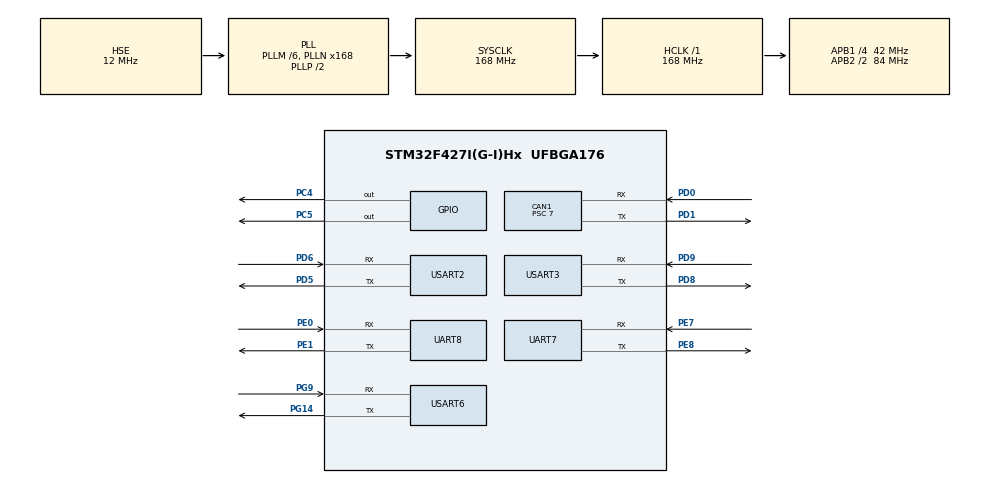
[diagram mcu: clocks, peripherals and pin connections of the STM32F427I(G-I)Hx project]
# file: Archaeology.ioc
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CAN1.ABOM=ENABLE
CAN1.AWUM=ENABLE
CAN1.BS1=CAN_BS1_2TQ
CAN1.BS2=CAN_BS2_3TQ
CAN1.CalculateBaudRate=1000000
CAN1.CalculateTimeBit=999.99
CAN1.CalculateTimeQuantum=166.66666666666669
CAN1.Mode=CAN_MODE_NORMAL
CAN1.Prescaler=7
CAN1.TXFP=ENABLE
Dma.Request0=USART3_TX
Dma.Request1=UART7_TX
Dma.Request2=UART8_TX
Dma.Request3=USART2_TX
Dma.Request4=USART6_TX
Dma.UART7_TX.1.Direction=DMA_MEMORY_TO_PERIPH
Dma.UART7_TX.1.FIFOMode=DMA_FIFOMODE_DISABLE
Dma.UART7_TX.1.Instance=DMA1_Stream1
Dma.UART7_TX.1.MemDataAlignment=DMA_MDATAALIGN_BYTE
Dma.UART7_TX.1.MemInc=DMA_MINC_ENABLE
Dma.UART7_TX.1.Mode=DMA_NORMAL
Dma.UART7_TX.1.PeriphDataAlignment=DMA_PDATAALIGN_BYTE
Dma.UART7_TX.1.PeriphInc=DMA_PINC_DISABLE
Dma.UART7_TX.1.Priority=DMA_PRIORITY_LOW
Dma.UART8_TX.2.Direction=DMA_MEMORY_TO_PERIPH
Dma.UART8_TX.2.FIFOMode=DMA_FIFOMODE_DISABLE
Dma.UART8_TX.2.Instance=DMA1_Stream0
Dma.UART8_TX.2.MemDataAlignment=DMA_MDATAALIGN_BYTE
Dma.UART8_TX.2.MemInc=DMA_MINC_ENABLE
Dma.UART8_TX.2.Mode=DMA_NORMAL
Dma.UART8_TX.2.PeriphDataAlignment=DMA_PDATAALIGN_BYTE
Dma.UART8_TX.2.PeriphInc=DMA_PINC_DISABLE
Dma.UART8_TX.2.Priority=DMA_PRIORITY_LOW
Dma.USART2_TX.3.Direction=DMA_MEMORY_TO_PERIPH
Dma.USART2_TX.3.FIFOMode=DMA_FIFOMODE_DISABLE
Dma.USART2_TX.3.Instance=DMA1_Stream6
Dma.USART2_TX.3.MemDataAlignment=DMA_MDATAALIGN_BYTE
Dma.USART2_TX.3.MemInc=DMA_MINC_ENABLE
Dma.USART2_TX.3.Mode=DMA_NORMAL
Dma.USART2_TX.3.PeriphDataAlignment=DMA_PDATAALIGN_BYTE
Dma.USART2_TX.3.PeriphInc=DMA_PINC_DISABLE
Dma.USART2_TX.3.Priority=DMA_PRIORITY_LOW
Dma.USART3_TX.0.Direction=DMA_MEMORY_TO_PERIPH
Dma.USART3_TX.0.FIFOMode=DMA_FIFOMODE_DISABLE
Dma.USART3_TX.0.Instance=DMA1_Stream3
Dma.USART3_TX.0.MemDataAlignment=DMA_MDATAALIGN_BYTE
Dma.USART3_TX.0.MemInc=DMA_MINC_ENABLE
Dma.USART3_TX.0.Mode=DMA_NORMAL
Dma.USART3_TX.0.PeriphDataAlignment=DMA_PDATAALIGN_BYTE
Dma.USART3_TX.0.PeriphInc=DMA_PINC_DISABLE
Dma.USART3_TX.0.Priority=DMA_PRIORITY_LOW
Dma.USART6_TX.4.Direction=DMA_MEMORY_TO_PERIPH
Dma.USART6_TX.4.FIFOMode=DMA_FIFOMODE_DISABLE
Dma.USART6_TX.4.Instance=DMA2_Stream6
Dma.USART6_TX.4.MemDataAlignment=DMA_MDATAALIGN_BYTE
Dma.USART6_TX.4.MemInc=DMA_MINC_ENABLE
Dma.USART6_TX.4.Mode=DMA_NORMAL
Dma.USART6_TX.4.PeriphDataAlignment=DMA_PDATAALIGN_BYTE
Dma.USART6_TX.4.PeriphInc=DMA_PINC_DISABLE
Dma.USART6_TX.4.Priority=DMA_PRIORITY_LOW
Mcu.Family=STM32F4
Mcu.Name=STM32F427I(G-I)Hx
Mcu.Package=UFBGA176
NVIC.CAN1_RX0_IRQn=true\:0\:0\:false\:false\:true\:true\:true
NVIC.CAN1_TX_IRQn=true\:0\:0\:false\:false\:true\:true\:true
NVIC.DMA1_Stream0_IRQn=true\:0\:0\:false\:false\:true\:false\:true
NVIC.DMA1_Stream1_IRQn=true\:0\:0\:false\:false\:true\:false\:true
NVIC.DMA1_Stream3_IRQn=true\:0\:0\:false\:false\:true\:false\:true
NVIC.DMA1_Stream6_IRQn=true\:0\:0\:false\:false\:true\:false\:true
NVIC.DMA2_Stream6_IRQn=true\:0\:0\:false\:false\:true\:false\:true
NVIC.PriorityGroup=NVIC_PRIORITYGROUP_4
NVIC.TIM6_DAC_IRQn=true\:0\:0\:false\:false\:true\:true\:true
NVIC.TIM7_IRQn=true\:0\:0\:false\:false\:true\:true\:true
NVIC.UART7_IRQn=true\:1\:0\:true\:false\:true\:true\:true
NVIC.UART8_IRQn=true\:0\:0\:false\:false\:true\:true\:true
NVIC.USART2_IRQn=true\:0\:0\:false\:false\:true\:true\:true
NVIC.USART3_IRQn=true\:0\:0\:false\:false\:true\:true\:true
NVIC.USART6_IRQn=true\:0\:0\:false\:false\:true\:true\:true
PA13.Mode=Serial_Wire
PA13.Signal=SYS_JTMS-SWDIO
PA14.Mode=Serial_Wire
PA14.Signal=SYS_JTCK-SWCLK
PC4.Signal=GPIO_Output
PC5.Signal=GPIO_Output
PD0.Mode=CAN_Activate
PD0.Signal=CAN1_RX
PD1.Mode=CAN_Activate
PD1.Signal=CAN1_TX
PD5.Mode=Asynchronous
PD5.Signal=USART2_TX
PD6.Mode=Asynchronous
PD6.Signal=USART2_RX
PD8.Mode=Asynchronous
PD8.Signal=USART3_TX
PD9.Mode=Asynchronous
PD9.Signal=USART3_RX
PE0.Mode=Asynchronous
PE0.Signal=UART8_RX
PE1.Mode=Asynchronous
PE1.Signal=UART8_TX
PE7.Mode=Asynchronous
PE7.Signal=UART7_RX
PE8.Mode=Asynchronous
PE8.Signal=UART7_TX
PG14.Mode=Asynchronous
PG14.Signal=USART6_TX
PG9.Mode=Asynchronous
PG9.Signal=USART6_RX
PH0/OSC_IN.Mode=HSE-External-Oscillator
PH0/OSC_IN.Signal=RCC_OSC_IN
PH1/OSC_OUT.Mode=HSE-External-Oscillator
PH1/OSC_OUT.Signal=RCC_OSC_OUT
ProjectManager.HeapSize=0x200
ProjectManager.StackSize=0x400
ProjectManager.TargetToolchain=MDK-ARM V5
RCC.48MHZClocksFreq_Value=84000000
RCC.AHBFreq_Value=168000000
RCC.APB1CLKDivider=RCC_HCLK_DIV4
RCC.APB1Freq_Value=42000000
RCC.APB1TimFreq_Value=84000000
RCC.APB2CLKDivider=RCC_HCLK_DIV2
RCC.APB2Freq_Value=84000000
RCC.APB2TimFreq_Value=168000000
RCC.CortexFreq_Value=168000000
RCC.HCLKFreq_Value=168000000
RCC.HSE_VALUE=12000000
RCC.HSI_VALUE=16000000
RCC.LSE_VALUE=32768
RCC.PLLM=6
RCC.PLLN=168
RCC.PLLSourceVirtual=RCC_PLLSOURCE_HSE
RCC.SYSCLKFreq_VALUE=168000000
RCC.SYSCLKSource=RCC_SYSCLKSOURCE_PLLCLK
RCC.VCOOutputFreq_Value=336000000
TIM6.AutoReloadPreload=TIM_AUTORELOAD_PRELOAD_DISABLE
TIM6.Period=30000-1
TIM6.Prescaler=42000-1
TIM7.Period=20000
TIM7.Prescaler=84-1
UART7.VirtualMode=Asynchronous
UART8.VirtualMode=Asynchronous
USART2.VirtualMode=VM_ASYNC
USART3.VirtualMode=VM_ASYNC
USART6.VirtualMode=VM_ASYNC
VP_TIM6_VS_ClockSourceINT.Mode=Enable_Timer
VP_TIM7_VS_ClockSourceINT.Mode=Enable_Timer
board=custom

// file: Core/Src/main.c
/* USER CODE BEGIN Header */
/**
  ******************************************************************************
  * @file           : main.c
  * @brief          : Main program body
  ******************************************************************************
  * @attention
  *
  * <h2><center>&copy; Copyright (c) 2021 STMicroelectronics.
  * All rights reserved.</center></h2>
  *
  * This software component is licensed by ST under BSD 3-Clause license,
  * the "License"; You may not use this file except in compliance with the
  * License. You may obtain a copy of the License at:
  *                        opensource.org/licenses/BSD-3-Clause
  *
  ******************************************************************************
  */
/* USER CODE END Header */
#include "main.h"
#include "can.h"
#include "dma.h"
#include "tim.h"
#include "usart.h"
#include "gpio.h"

/* USER CODE BEGIN Includes */
#include "USER_TIM.h"
#include "Bucket.h"
#include "PC.h"
#include "Laser.h"
#include "USER_CAN.h"
#include "Crc.h"
/* USER CODE END Includes */

void SystemClock_Config(void);

int main(void)
{

  /* MCU Configuration--------------------------------------------------------*/

  /* Reset of all peripherals, Initializes the Flash interface and the Systick. */
  HAL_Init();

  /* Configure the system clock */
  SystemClock_Config();

  /* Initialize all configured peripherals */
  MX_GPIO_Init();
  MX_DMA_Init();
  MX_UART7_Init();
  MX_UART8_Init();
  MX_USART2_UART_Init();
  MX_USART3_UART_Init();
  MX_USART6_UART_Init();
  MX_TIM7_Init();
  MX_TIM6_Init();
  MX_CAN1_Init();
  /* USER CODE BEGIN 2 */
	PC_Init();//开启串口接收中断
	Laser_Init();
	USER_CAN_Init();
	USER_TIM_Init();
  /* USER CODE END 2 */

  /* Infinite loop */
  while (1)
  {

  }
}

void SystemClock_Config(void)
{
  RCC_OscInitTypeDef RCC_OscInitStruct = {0};
  RCC_ClkInitTypeDef RCC_ClkInitStruct = {0};

  /** Configure the main internal regulator output voltage
  */
  __HAL_RCC_PWR_CLK_ENABLE();
  __HAL_PWR_VOLTAGESCALING_CONFIG(PWR_REGULATOR_VOLTAGE_SCALE1);
  /** Initializes the RCC Oscillators according to the specified parameters
  * in the RCC_OscInitTypeDef structure.
  */
  RCC_OscInitStruct.OscillatorType = RCC_OSCILLATORTYPE_HSE;
  RCC_OscInitStruct.HSEState = RCC_HSE_ON;
  RCC_OscInitStruct.PLL.PLLState = RCC_PLL_ON;
  RCC_OscInitStruct.PLL.PLLSource = RCC_PLLSOURCE_HSE;
  RCC_OscInitStruct.PLL.PLLM = 6;
  RCC_OscInitStruct.PLL.PLLN = 168;
  RCC_OscInitStruct.PLL.PLLP = RCC_PLLP_DIV2;
  RCC_OscInitStruct.PLL.PLLQ = 4;
  if (HAL_RCC_OscConfig(&RCC_OscInitStruct) != HAL_OK)
  {
    Error_Handler();
  }
  /** Initializes the CPU, AHB and APB buses clocks
  */
  RCC_ClkInitStruct.ClockType = RCC_CLOCKTYPE_HCLK|RCC_CLOCKTYPE_SYSCLK
                              |RCC_CLOCKTYPE_PCLK1|RCC_CLOCKTYPE_PCLK2;
  RCC_ClkInitStruct.SYSCLKSource = RCC_SYSCLKSOURCE_PLLCLK;
  RCC_ClkInitStruct.AHBCLKDivider = RCC_SYSCLK_DIV1;
  RCC_ClkInitStruct.APB1CLKDivider = RCC_HCLK_DIV4;
  RCC_ClkInitStruct.APB2CLKDivider = RCC_HCLK_DIV2;

  if (HAL_RCC_ClockConfig(&RCC_ClkInitStruct, FLASH_LATENCY_5) != HAL_OK)
  {
    Error_Handler();
  }
}

void Error_Handler(void)
{
  __disable_irq();
  while (1)
  {
  }
}

/************************ (C) COPYRIGHT STMicroelectronics *****END OF FILE****/
